# AT32F421 register map
Vendor: Keil; Series: AT32F421; File version: 1.0
ARM 32-bit Cortex-M4 Microcontroller based device, CPU clock up to 200MHz, etc.
CPU: CM4 r0p1, little endian, no MPU, FPU, 4 interrupt priority bits
Registers are 32-bit, read-write, reset 0x0 unless marked. A register's access mark holds for its fields unless they carry their own. Offsets are from the block's base; lines under a group give offsets from that group; [hi:lo] are bit positions; {n}, {i} and the like mark numbered series; 'fields as' and 'values as' point back to an identical list; <NAME> marks a mode.

## Memory map
0x40000400 TMR3 size 0x400 — General purpose timer
0x40001000 TMR6 size 0x400 — Basic timer
0x40002000 TMR14 size 0x400 — General purpose timer
0x40002800 ERTC size 0x400 — Real-time clock
0x40002C00 WWDT size 0x400 — Window watchdog
0x40003000 WDT size 0x400 — Watchdog
0x40003800 SPI2 size 0x400
0x40004400 USART2 size 0x400
0x40005400 I2C1 size 0x400 — Inter integrated circuit
0x40005800 I2C2 size 0x400
0x40007000 PWC size 0x400 — Power control
0x40010000 SCFG size 0x1C — System configuration controller
0x4001001C CMP size 0x3E4 — Comparator
0x40010400 EXINT size 0x400
0x40012400 ADC1 size 0x400 — Analog to digital converter
0x40012C00 TMR1 size 0x400 — Advanced timer
0x40013000 SPI1 size 0x400 — Serial peripheral interface
0x40013800 USART1 size 0x400 — Universal synchronous asynchronous receiver transmitter
0x40014000 TMR15 size 0x400 — Advanced timer
0x40014400 TMR16 size 0x400 — General purpose timer
0x40014800 TMR17 size 0x400
0x40020000 DMA1 size 0x400 — DMA controller
0x40021000 CRM size 0x400 — Clock and reset management
0x40022000 FLASH size 0x400 — Flash memory controler
0x40023000 CRC size 0x400 — CRC calculation unit
0x48000000 GPIOA size 0x400 — General purpose I/Os
0x48000400 GPIOB size 0x400
0x48000800 GPIOC size 0x400
0x48001400 GPIOF size 0x400
0xE000E000 NVIC size 0x1001 — Nested Vectored Interrupt Controller
0xE0042000 DEBUG size 0x400 — Debug support

## Interrupts
0 WWDT — Window Watchdog interrupt
1 PVM (EXINT) — PVM interrupt connect to EXTI line16
2 ERTC (EXINT) — ERTC interrupt connect to EXTI line17_19
3 FLASH — Flash global interrupt
4 CRM — CRM global interrupt
5 EXTINT1_0 (EXINT) — EXINT Line1_0 interrupt
6 EXTINT3_2 (EXINT) — EXINT Line3_2 interrupt
7 EXTINT15_4 (EXINT) — EXINT Line15_4 interrupt
9 DMA1_Channel1 (DMA1) — DMA1 Channel1 global interrupt
10 DMA1_Channel3_2 (DMA1) — DMA1 Channel2 global interrupt
11 DMA1_Channel5_4 (DMA1) — DMA1 Channel3 global interrupt
12 ADC_CMP (ADC1, CMP)
13 TMR1_BRK_OVF_TRG_HALL (TMR1) — TMR1 overflow brake trigger hall interrupt
14 TMR1_CH (TMR1) — TMR1 channel interrupt
16 TMR3 — TMR3 global interrupt
17 TMR6 — TMR6 global interrupt
19 TMR14 — TMR14 global interrupt
20 TMR15 — TMR15 global interrupt
21 TMR16 — TMR16 global interrupt
22 TMR17 — TMR17 global interrupt
27 USART1 — USART1 global interrupt
28 USART2 — USART2 global interrupt
31 I2C1_EVT (I2C1) — I2C1 event interrupt
32 I2C1_ERR (I2C1) — I2C1 error interrupt
33 I2C2_EVT (I2C2) — I2C2 event interrupt
34 I2C2_ERR (I2C2) — I2C2 error interrupt
35 SPI1 — SPI1 global interrupt
36 SPI2 — SPI2 global interrupt

## PWC — Power control
Base 0x40007000
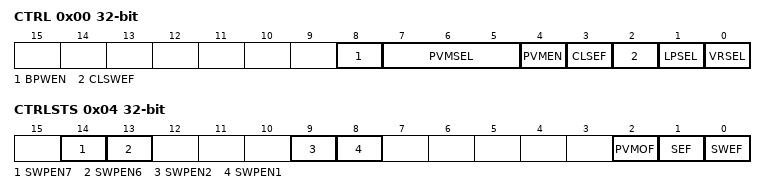
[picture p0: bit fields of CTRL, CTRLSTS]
0x00 CTRL — Power control register (PWC_CTRL)
  [8] BPWEN — Battery powered domain write enable
    0=Disabled (Battery powered domain write disabled); 1=Enabled (Battery powered domain write enabled)
  [7:5] PVMSEL — Power voltage monitoring boundary select
    1=v2_3 (2.3V); 2=v2_4 (2.4V); 3=v2_5 (2.5V); 4=v2_6 (2.6V); 5=v2_7 (2.7V); 6=v2_8 (2.8V); 7=v2_9 (2.9V)
  [4] PVMEN — Power voltage monitoring enable
    0=Disabled (Power voltage monitoring disabled); 1=Enabled (Power voltage monitoring enabled)
  [3] CLSEF wo write-1-clears — Clear SEF flag
    1=Clear the flag
  [2] CLSWEF wo write-1-clears — Clear SWEF flag
    1=Clear the flag
  [1] LPSEL — Low power mode select when Cortex-M4F sleepdeep
    0=Enter deepsleep mode when the CPU enters deepsleep mode; 1=Enter standby mode when the CPU enters deepsleep mode
  [0] VRSEL — Voltage regulator state select when deepsleep mode
    0=Enabled (LDO enabled in deepsleep mode); 1=Disabled (LDO disabled in deepsleep mode)
0x04 CTRLSTS — Power control and status register (PWC_CTRLSTS)
  [14] SWPEN7 — Standby wake-up pin2 enable
    0=Disabled; 1=Enabled
  [13] SWPEN6 — Standby wake-up pin2 enable
    0=Disabled; 1=Enabled
  [9] SWPEN2 — Standby wake-up pin2 enable
    0=Disabled; 1=Enabled
  [8] SWPEN1 — Standby wake-up pin1 enable
    0=Disabled; 1=Enabled
  [2] PVMOF ro — Power voltage monitoring output flag
    0=Higher (Power voltage is higher than the threshold); 1=Lower (Power voltage is lower than the threshold)
  [1] SEF ro — Standby mode entry flag
    0=NoStandby (Device is not in standby mode); 1=Standby (Device is in standby mode)
  [0] SWEF ro — Standby wake-up event flag
    0=No wakeup event occurred; 1=Wakeup event occurred
